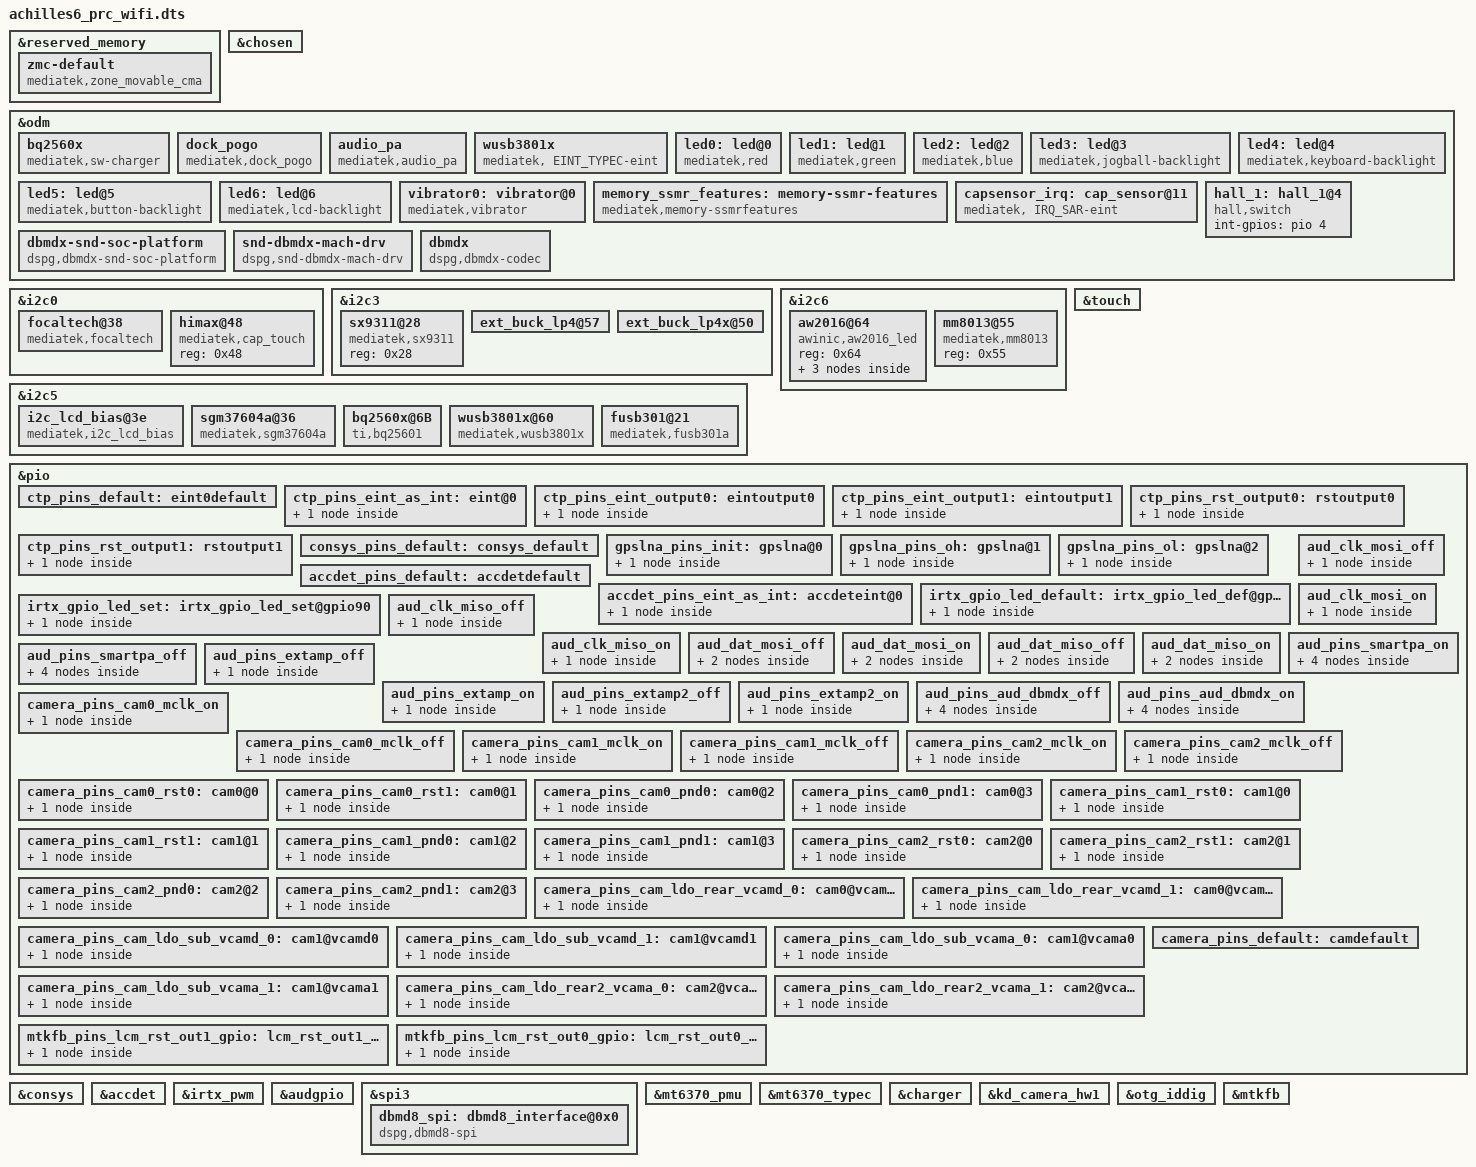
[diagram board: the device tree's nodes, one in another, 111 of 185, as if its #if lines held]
#include <dt-bindings/interrupt-controller/arm-gic.h>
#include <dt-bindings/interrupt-controller/irq.h>
#include <dt-bindings/pinctrl/mt6765-pinfunc.h>
#include <dt-bindings/clock/mt6765-clk.h>
#include <dt-bindings/sound/dspg.h>

/dts-v1/;
/plugin/;
&reserved_memory {
 #address-cells = <2>;
 #size-cells = <2>;
 ranges;
 zmc-default {
 compatible = "mediatek,zone_movable_cma";
 size = <0 0x10000000>;
 alignment = <0 0x10000000>;
 alloc-ranges = <0 0 1 0x00000000>;
 };
};

/* chosen */
&chosen {

	/* fpga may has no lk, we need to specify display info here */
	/* fb buffer is reserved using this dts by memory node above */
	atag,videolfb-fb_base_h = <0x0>;
	atag,videolfb-fb_base_l = <0x5e605000>;
	atag,videolfb-islcmfound = <1>;
	/* because no lk, so lcm is not inited */
	atag,videolfb-islcm_inited = <0>;
	atag,videolfb-fps= <6000>;
	atag,videolfb-vramSize= <0x017bb000>;
	atag,videolfb-lcmname= "nt35695B_fhd_dsi_cmd_auo_rt5081_drv";
};

&odm {
	bq2560x{
		compatible = "mediatek,sw-charger";
		interrupt-parent = <&pio>;
		interrupts = <2 IRQ_TYPE_LEVEL_LOW 2 0>;
		status = "okay";
	};

	dock_pogo{
		compatible = "mediatek,dock_pogo";
		usb_status = <&pio 9 0>;
		dock_status = <&pio 5 0>;
	};

	audio_pa{
		compatible = "mediatek,audio_pa";
		extamp_1 = <&pio 151 0>;
		extamp_2 = <&pio 153 0>;
	};

	wusb3801x {
		compatible = "mediatek, EINT_TYPEC-eint";
		interrupt-parent = <&pio>;
		interrupts = <152 IRQ_TYPE_LEVEL_LOW 152 0>;
		status = "okay";
	};

	led0:led@0 {
		compatible = "mediatek,red";
		led_mode = <0>;
		data = <1>;
		pwm_config = <0 0 0 0 0>;
	};
	led1:led@1 {
		compatible = "mediatek,green";
		led_mode = <0>;
		data = <1>;
		pwm_config = <0 0 0 0 0>;
	};
	led2:led@2 {
		compatible = "mediatek,blue";
		led_mode = <0>;
		data = <1>;
		pwm_config = <0 0 0 0 0>;
	};
	led3:led@3 {
		compatible = "mediatek,jogball-backlight";
		led_mode = <0>;
		data = <1>;
		pwm_config = <0 0 0 0 0>;
	};
	led4:led@4 {
		compatible = "mediatek,keyboard-backlight";
		led_mode = <0>;
		data = <1>;
		pwm_config = <0 0 0 0 0>;
	};
	led5:led@5 {
		compatible = "mediatek,button-backlight";
		led_mode = <0>;
		data = <1>;
		pwm_config = <0 0 0 0 0>;
	};
	led6:led@6 {
		compatible = "mediatek,lcd-backlight";
		led_mode = <4>;
		data = <1>;
		pwm_config = <0 3 0 0 0>;
	};
	vibrator0:vibrator@0 {
		compatible = "mediatek,vibrator";
		vib_timer = <25>;
		vib_limit = <9>;
		vib_vol= <9>;
	};
	memory_ssmr_features: memory-ssmr-features {
		compatible = "mediatek,memory-ssmrfeatures";
		svp-size = <0 0x10000000>;
		iris-recognition-size = <0 0>;
		2d_fr-size = <0 0>;
		tui-size = <0 0>;
		wfd-size = <0 0>;
		prot-sharedmem-size = <0 0>;
	};
	capsensor_irq:cap_sensor@11 {
                compatible = "mediatek, IRQ_SAR-eint";
                interrupt-parent = <&pio>;
		interrupts = <11 IRQ_TYPE_EDGE_FALLING 11 0>;
		status = "okay";
        };
	hall_1:hall_1@4 {
                compatible = "hall,switch";
                int-gpios = <&pio 4 0>;
		status = "okay";
       };

	 dbmdx-snd-soc-platform {
                   compatible = "dspg,dbmdx-snd-soc-platform";
         };

         snd-dbmdx-mach-drv {
                   compatible = "dspg,snd-dbmdx-mach-drv";
         };

	dbmdx {
		status = "okay";
		compatible = "dspg,dbmdx-codec";
		reset_gpio_shared = <0>;
		reset-gpio = <&pio 42 0>;
		sv-gpio = <&pio 7 0>;
		wakeup-gpio = <&pio 6 0>;
		auto_buffering = <1>;
		multi-interface-support = <1>;
		cd-interfaces = < &dbmd8_spi >;
		va-interfaces = <0 0 0 0>;
		feature-va_ve; /* enable VA_VE */
		va-firmware-name = "dbmd8_va_fw.bin";
		va-preboot-firmware-name = "dbmd8_va_preboot_fw.bin";
		va-config =	<DBMDX_VA_EMPTY_CMD
				DBMDX_VA_EMPTY_CMD
				DBMDX_VA_EMPTY_CMD
				(DBMDX_REGN_HOST_INTERFACE_SUPPORT |
					DBMDX_REGV_SPI_D2_TDM1_D4_GPIO_4_5_6_7)
				(DBMDX_REGN_MASTER_CLOCK_FREQUENCY |
#if DBMDX_MCLOCK_VA_24MHZ
					DBMDX_REGV_MCLK_24576000Hz)
#elif DBMDX_MCLOCK_VA_12MHZ
					DBMDX_REGV_MCLK_12288000Hz)
#else /* 32KHZ */
					DBMDX_REGV_MCLK_32768Hz)
#endif
				(DBMDX_REGN_AUDIO_BUFFER_SIZE |
					DBMDX_REGV_AUDIO_BUFFER_3_SEC)
				(DBMDX_REGN_GENERAL_CONFIG_1 |
#ifdef DBMDX_USE_RC_OSC
					DBMDX_REGV_DSP_CLK_GEN_RC_OSC |
#else
					DBMDX_REGV_DSP_CLK_GEN_PLL |
#endif
					DBMDX_REGV_IF_REQUIRED_WAKEUP |
					DBMDX_REGV_SPLIT_MIC_BUFFER |
					DBMDX_REGV_MAX_NUMBER_OF_MIC_IS_2)
																												  
				(DBMDX_REGN_MEMORY_CONFIG |
					DBMDX_REGV_AMODEL_0_LOC_DTCM |
					DBMDX_REGV_AMODEL_1_LOC_DTCM |
					DBMDX_REGV_AMODEL_4_LOC_DTCM |
					DBMDX_REGV_AUDIO_BUF_LOC_DTCM_USING_MEM_ALLOCATION |
#if DBMDX_OKG_WWE_SUPPORT && DBMDX_AMAZON_WWE_SUPPORT
					DBMDX_REGV_AHB_ON_SIZE_192KW_32KW_CACHE_D8 |
#else
					DBMDX_REGV_AHB_ON_SIZE_112KW_32KW_CACHE |
#endif
					DBMDX_REGV_DTCM_SIZE_D4_D6_96_KW_D8_192KW)

				(DBMDX_REGN_GENERAL_CONFIG_2 |
					DBMDX_REGV_MIC_SAMPLE_RATE_16K |
					DBMDX_REGV_DDF_SAMPLE_WIDTH_16_BIT |
					DBMDX_REGV_FW_VAD_TYPE_NO_VAD)
#if DBMDX_USE_ANALOG_MICS
				(DBMDX_REGN_HPF_ENABLE_DISABLE |
					0x0013 )
#else
				(DBMDX_REGN_HPF_ENABLE_DISABLE |
					0x0010 |
					DBMDX_REGV_IIR_HPF_EN |
					DBMDX_REGV_DC_REMOVE_COARSE_EN)
#endif

				(DBMDX_REGN_GPIO_CONFIG |
					DBMDX_REGV_SET_SEC_GPIO |
					DBMDX_REGV_SEC_MODEL_DET_GPIO_NUM_12 |
					DBMDX_REGV_SET_PRI_GPIO |
					DBMDX_REGV_PRI_MODEL_DET_GPIO_NUM_12 )
				(DBMDX_REGN_DSP_CLOCK_CONFIG |
#if DBMDX_MCLOCK_VA_24MHZ
					DBMDX_REGV_PLL_STEP_3 |
#elif DBMDX_MCLOCK_VA_12MHZ
					DBMDX_REGV_PLL_STEP_6 |
#else /* 32Khz */
					DBMDX_REGV_PLL_STEP_4 |
#endif
					DBMDX_REGV_TL3_DIV_1 |
					DBMDX_REGV_APB_DIV_1 |
					DBMDX_REGV_AHB_DIV_3)

				(DBMDX_VA_MSLEEP | 0x0040)
				(DBMDX_REGN_UART_SPEED |
					DBMDX_REGV_UART_BAUD_RATE_3_Mhz)
#ifdef DBMDX_USE_ANALOG_MICS
				(DBMDX_REGN_FIRST_MICROPHONE_CONFIG |
					DBMDX_REGV_DDF_AUDIO_ATTENUATION_0dB |
					DBMDX_REGV_DDF_AND_DM_CONFIG_SAR_DDF_SAR_ADC)
				(DBMDX_REGN_SECOND_MICROPHONE_CONFIG |
					DBMDX_REGV_DDF_AUDIO_ATTENUATION_0dB |
					DBMDX_REGV_DM_CLK_FREQ_1536_1200_SR_8KHz_16KHz_32KHz_48KHz |
					DBMDX_REGV_DDF_AND_DM_CONFIG_SD_DDF_SD_ADC)
#else
				(DBMDX_REGN_FIRST_MICROPHONE_CONFIG |
					DBMDX_REGV_DM_CLOCK_SRC_DM0_GPIO8_DM1_GPIO14 |
		 			DBMDX_REGV_DM_DATA_SRC_DM0_GPIO9_DM1_GPIO13 |
		 			DBMDX_REGV_DDF_AUDIO_ATTENUATION_0dB |
					DBMDX_REGV_DM_CLK_FREQ_1536_1200_SR_8KHz_16KHz_32KHz_48KHz |
					DBMDX_REGV_CLOCK_POLARITY_FALLING_EDGE |
					DBMDX_REGV_DDF_AND_DM_CONFIG_DF0_DM0)
				(DBMDX_REGN_SECOND_MICROPHONE_CONFIG |
					DBMDX_REGV_DM_CLOCK_SRC_DM0_GPIO8_DM1_GPIO14 |
					DBMDX_REGV_DM_DATA_SRC_DM0_GPIO9_DM1_GPIO13 |
					DBMDX_REGV_DDF_AUDIO_ATTENUATION_0dB |
					DBMDX_REGV_DM_CLK_FREQ_1536_1200_SR_8KHz_16KHz_32KHz_48KHz |
					DBMDX_REGV_CLOCK_POLARITY_RISING_EDGE |
					DBMDX_REGV_DDF_AND_DM_CONFIG_DDF1_DM0)
#endif
				(DBMDX_REGN_SECOND_MICROPHONE_CONFIG |
					DBMDX_REGV_CLOSING_MICS_NO_DM_CLOCK)
				(DBMDX_REGN_FIRST_MICROPHONE_CONFIG |
					DBMDX_REGV_CLOSING_MICS_NO_DM_CLOCK)

				DBMDX_VA_EMPTY_CMD
				DBMDX_VA_EMPTY_CMD
				DBMDX_VA_EMPTY_CMD>;

		va-speeds = <0x0000 460800  0 1000000
			     0x0000 2000000 0 3000000
			     0x0000 3000000 0 5000000>;
		va-mic-config = <0x5076 0xa061 0x0A68>;
                va_ve-mic-config = <0x5076 0xa061 0xa093 0x0000>;
                va-mic-mode = <4>;
		master-clk-rate = <32768>;
		default_va_clock = <98304000>;
		/* constant-clk-rate = <32768>; */
		auto_detection = <1>;
		firmware_id = <0xdbd8>;
		wakeup_disabled = <0>;
		use_gpio_for_wakeup = <1>; /* Use wakeup gpio */
		send_wakeup_seq = <0>; /* Send wakup seq */
		wakeup_set_value = <0>;

		uart_low_speed_enabled = <1>;
		detection_buffer_channels = <0>;
		pcm_streaming_mode = <1>;
		boot_options = <0x220>; /* Verify chip id */
		send_uevent_on_detection = <1>;
		send_uevent_after_buffering = <1>;
		detection_after_buffering = <2>;
		change_clock_src_options = <0x4003>;
		va_backlog_length = <502>;
		qed_enabled = <0>;
		low_power_mode_disabled = <0>;
		hw_revision = <0>;
		project_sub_type = <1>;	/* VT ONLY - MELON */
		buffering_timeout = <5>;
		default-streaming-usecase-name = "uc_melon_ga_2mic_aec_48k";
		alsa_streaming_options = <0x8>;
		asrp_tx_out_gain = <0x2cfc>; /* gain=15: (int)((10^(gain/20))*2048) */
		asrp_vcpf_out_gain = <0x2cfc>; /* gain=15: (int)((10^(gain/20))*2048) */
		asrp_rx_out_gain = <0x2cfc>; /* gain=15: (int)((10^(gain/20))*2048) */
		asrp_delay = <1>;
		amodel_options = <1>;
	};

};

&i2c0 {
	focaltech@38 {
		compatible = "mediatek,focaltech";
		reg = <0x38>;
		status = "okay";
		focaltech,usb-charger;
	};

	himax@48 {
		compatible = "mediatek,cap_touch";
		reg = <0x48>;
		status = "okay";
	};
};

&i2c3 {
	sx9311@28 {
                compatible = "mediatek,sx9311";
                reg = <0x28>;
		status = "okay" ;
        };

	ext_buck_lp4@57 {
		regulator-name ="ext_buck_vdd2";
		regulator-min-microvolt = <300000>;
		regulator-max-microvolt = <1300000>;
		vsel_pin = <0>;
	};

	ext_buck_lp4x@50 {
		regulator-name ="ext_buck_vddq";
		regulator-min-microvolt = <300000>;
		regulator-max-microvolt = <1300000>;
		vsel_pin = <1>;
	};
};

&i2c5 {
	i2c_lcd_bias@3e {
		compatible = "mediatek,i2c_lcd_bias";
		reg = <0x3e>;
		bias_gpio_enn = <&pio 168 0>;
		bias_gpio_enp = <&pio 167 0>;
		status = "okay";
	};

	sgm37604a@36 {
		compatible = "mediatek,sgm37604a";
		reg = <0x36>;
		lcm_bl_gpio_enable = <&pio 154 0>;
		status = "okay";
	};
};

&i2c6 {
	aw2016@64 {/* add for breath led. */
		compatible = "awinic,aw2016_led";
		reg = <0x64>;

		aw2016,red {
			aw2016,name = "red";
			aw2016,id = <0>;
			aw2016,imax = <2>;
			aw2016,led-current = <3>;
			aw2016,max-brightness = <255>;
			aw2016,rise-time-ms = <6>;
			aw2016,hold-time-ms = <0>;
			aw2016,fall-time-ms = <6>;
			aw2016,off-time-ms = <4>;
		};

		aw2016,green {
			aw2016,name = "green";
			aw2016,id = <1>;
			aw2016,imax = <3>;
			aw2016,led-current = <3>;
			aw2016,max-brightness = <255>;
			aw2016,rise-time-ms = <6>;
			aw2016,hold-time-ms = <0>;
			aw2016,fall-time-ms = <6>;
			aw2016,off-time-ms = <4>;
		};

		aw2016,blue {
			aw2016,name = "blue";
			aw2016,id = <2>;
			aw2016,imax = <2>;
			aw2016,led-current = <3>;
			aw2016,max-brightness = <255>;
			aw2016,rise-time-ms = <6>;
			aw2016,hold-time-ms = <0>;
			aw2016,fall-time-ms = <6>;
			aw2016,off-time-ms = <4>;
		};
	};
};

/* TOUCH start */
&touch {
	tpd-resolution = <1200 1920>;
	use-tpd-button = <0>;
	tpd-key-num = <3>;
	tpd-key-local= <139 172 158 0>;
	tpd-key-dim-local = <90 883 100 40 230
				 883 100 40 370 883 100 40 0 0 0 0>;
	tpd-max-touch-num = <10>;
	tpd-filter-enable = <0>;
	tpd-filter-pixel-density = <146>;
	tpd-filter-custom-prameters = <0 0 0 0 0 0 0 0 0 0 0 0>;
	tpd-filter-custom-speed = <0 0 0>;
	pinctrl-names = "default", "state_eint_as_int", "state_eint_output0",
		"state_eint_output1", "state_rst_output0", "state_rst_output1";
	pinctrl-0 = <&ctp_pins_default>;
	pinctrl-1 = <&ctp_pins_eint_as_int>;
	pinctrl-2 = <&ctp_pins_eint_output0>;
	pinctrl-3 = <&ctp_pins_eint_output1>;
	pinctrl-4 = <&ctp_pins_rst_output0>;
	pinctrl-5 = <&ctp_pins_rst_output1>;
	status = "okay";
};
&pio {
	ctp_pins_default: eint0default {
	};
	ctp_pins_eint_as_int: eint@0 {
		pins_cmd_dat {
			pinmux = <PINMUX_GPIO10__FUNC_GPIO10>;
			slew-rate = <0>;
			bias-disable;
		};
	};
	ctp_pins_eint_output0: eintoutput0 {
		pins_cmd_dat {
			pinmux = <PINMUX_GPIO10__FUNC_GPIO10>;
			slew-rate = <1>;
			output-low;
		};
	};
	ctp_pins_eint_output1: eintoutput1 {
		pins_cmd_dat {
			pinmux = <PINMUX_GPIO10__FUNC_GPIO10>;
			slew-rate = <1>;
			output-high;
		};
	};
	ctp_pins_rst_output0: rstoutput0 {
		pins_cmd_dat {
			pinmux = <PINMUX_GPIO172__FUNC_GPIO172>;
			slew-rate = <1>;
			output-low;
		};
	};
	ctp_pins_rst_output1: rstoutput1 {
		pins_cmd_dat {
			pinmux = <PINMUX_GPIO172__FUNC_GPIO172>;
			slew-rate = <1>;
			output-high;
		};
	};
};
/* TOUCH end */

/* CONSYS GPIO standardization */
&pio {
	consys_pins_default: consys_default {
	};
	gpslna_pins_init: gpslna@0 {
		pins_cmd_dat {
			pinmux = <PINMUX_GPIO91__FUNC_GPIO91>;
			slew-rate = <0>;
			bias-disable;
			output-low;
		};
	};
	gpslna_pins_oh: gpslna@1 {
		pins_cmd_dat {
			pinmux = <PINMUX_GPIO91__FUNC_GPIO91>;
			slew-rate = <1>;
			output-high;
		};
	};
	gpslna_pins_ol: gpslna@2 {
		pins_cmd_dat {
			pinmux = <PINMUX_GPIO91__FUNC_GPIO91>;
			slew-rate = <1>;
			output-low;
		};
	};
};
&consys {
	pinctrl-names = "default", "gps_lna_state_init",
		"gps_lna_state_oh", "gps_lna_state_ol";
	pinctrl-0 = <&consys_pins_default>;
	pinctrl-1 = <&gpslna_pins_init>;
	pinctrl-2 = <&gpslna_pins_oh>;
	pinctrl-3 = <&gpslna_pins_ol>;
	status = "okay";
};
/* CONSYS end */

/* accdet start */
&accdet {
	accdet-mic-vol = <6>;
	headset-mode-setting = <0x500 0x500 1 0x1f0 0x800 0x800 0x20 0x44>;
	accdet-plugout-debounce = <1>;
	accdet-mic-mode = <1>;
	headset-eint-level-pol = <8>;
	headset-three-key-threshold = <0 80 220 400>;
	headset-three-key-threshold-CDD = <0 121 192 600>;
	headset-four-key-threshold = <0 58 121 192 400>;
	pinctrl-names = "default", "state_eint_as_int";
	pinctrl-0 = <&accdet_pins_default>;
	pinctrl-1 = <&accdet_pins_eint_as_int>;
	status = "okay";
};
&pio {
	accdet_pins_default: accdetdefault {
	};
	accdet_pins_eint_as_int: accdeteint@0 {
		pins_cmd_dat {
			pinmux = <PINMUX_GPIO9__FUNC_GPIO9>;
			slew-rate = <0>;
			bias-disable;
		};
	};
};
/* accdet end */


/* IRTX GPIO end */
&irtx_pwm {
	pinctrl-names = "irtx_gpio_led_default", "irtx_gpio_led_set";
	pinctrl-0 = <&irtx_gpio_led_default>;
	pinctrl-1 = <&irtx_gpio_led_set>;
	status = "okay";
};
&pio {
	irtx_gpio_led_default:irtx_gpio_led_def@gpio90 {
		pins_cmd_dat {
			pinmux = <PINMUX_GPIO90__FUNC_GPIO90>;
			slew-rate = <1>;
			bias-disable;
			output-low;
			input-schmitt-enable = <0>;
		};
	};

	irtx_gpio_led_set:irtx_gpio_led_set@gpio90 {
		pins_cmd_dat {
			pinmux = <PINMUX_GPIO90__FUNC_PWM0>;
			slew-rate = <1>;
			output-high;
		};
	};
};
/* IRTX GPIO Settings -End */

/* AUDIO GPIO standardization */
&audgpio {
	pinctrl-names = "aud_clk_mosi_off",
			"aud_clk_mosi_on",
			"aud_clk_miso_off",
			"aud_clk_miso_on",
			"aud_dat_mosi_off",
			"aud_dat_mosi_on",
			"aud_dat_miso_off",
			"aud_dat_miso_on",
			"aud_smartpa_off",
			"aud_smartpa_on",
			"extamp-pullhigh",
			"extamp-pulllow",
			"extamp2-pullhigh",
			"extamp2-pulllow",
			"aud_dbmdx_off",
			"aud_dbmdx_on";
	pinctrl-0 = <&aud_clk_mosi_off>;
	pinctrl-1 = <&aud_clk_mosi_on>;
	pinctrl-2 = <&aud_clk_miso_off>;
	pinctrl-3 = <&aud_clk_miso_on>;
	pinctrl-4 = <&aud_dat_mosi_off>;
	pinctrl-5 = <&aud_dat_mosi_on>;
	pinctrl-6 = <&aud_dat_miso_off>;
	pinctrl-7 = <&aud_dat_miso_on>;
	pinctrl-8 = <&aud_pins_smartpa_off>;
	pinctrl-9 = <&aud_pins_smartpa_on>;
	pinctrl-10 = <&aud_pins_extamp_on>;
	pinctrl-11 = <&aud_pins_extamp_off>;
	pinctrl-12 = <&aud_pins_extamp2_on>;
	pinctrl-13 = <&aud_pins_extamp2_off>;
	pinctrl-14 = <&aud_pins_aud_dbmdx_off>;
	pinctrl-15 = <&aud_pins_aud_dbmdx_on>;
	status = "okay";
};

&pio {
	aud_clk_mosi_off: aud_clk_mosi_off {
		pins_cmd0_dat {
			pinmux = <PINMUX_GPIO136__FUNC_GPIO136>;
		};
	};

	aud_clk_mosi_on: aud_clk_mosi_on {
		pins_cmd0_dat {
			pinmux = <PINMUX_GPIO136__FUNC_AUD_CLK_MOSI>;
		};
	};

	aud_clk_miso_off: aud_clk_miso_off {
		pins_cmd0_dat {
			pinmux = <PINMUX_GPIO140__FUNC_GPIO140>;
		};
	};

	aud_clk_miso_on: aud_clk_miso_on {
		pins_cmd0_dat {
			pinmux = <PINMUX_GPIO140__FUNC_AUD_CLK_MISO>;
		};
	};

	aud_dat_mosi_off: aud_dat_mosi_off {
		pins_cmd1_dat {
			pinmux = <PINMUX_GPIO138__FUNC_GPIO138>;
			input-enable;
			slew-rate = <0>;
			bias-disable;
		};
		pins_cmd2_dat {
			pinmux = <PINMUX_GPIO139__FUNC_GPIO139>;
			input-enable;
			slew-rate = <0>;
			bias-disable;
		};
	};

	aud_dat_mosi_on: aud_dat_mosi_on {
		pins_cmd1_dat {
			pinmux = <PINMUX_GPIO138__FUNC_AUD_DAT_MOSI0>;
		};
		pins_cmd2_dat {
			pinmux = <PINMUX_GPIO139__FUNC_AUD_DAT_MOSI1>;
		};
	};

	aud_dat_miso_off: aud_dat_miso_off {
		pins_cmd1_dat {
			pinmux = <PINMUX_GPIO142__FUNC_GPIO142>;
			input-enable;
			slew-rate = <0>;
			bias-disable;
		};
		pins_cmd2_dat {
			pinmux = <PINMUX_GPIO143__FUNC_GPIO143>;
			input-enable;
			slew-rate = <0>;
			bias-disable;
		};
	};

	aud_dat_miso_on: aud_dat_miso_on {
		pins_cmd1_dat {
			pinmux = <PINMUX_GPIO142__FUNC_AUD_DAT_MISO0>;
		};
		pins_cmd2_dat {
			pinmux = <PINMUX_GPIO143__FUNC_AUD_DAT_MISO1>;
		};
	};

	aud_pins_smartpa_off: aud_pins_smartpa_off {
		pins_cmd0_dat {
			pinmux = <PINMUX_GPIO17__FUNC_GPIO17>;
		};
		pins_cmd1_dat {
			pinmux = <PINMUX_GPIO18__FUNC_GPIO18>;
		};
		pins_cmd2_dat {
			pinmux = <PINMUX_GPIO19__FUNC_GPIO19>;
		};
		pins_cmd3_dat {
			pinmux = <PINMUX_GPIO20__FUNC_GPIO20>;
		};
	};

	aud_pins_smartpa_on: aud_pins_smartpa_on {
		pins_cmd0_dat {
			pinmux = <PINMUX_GPIO17__FUNC_I2S0_DI>;
		};
		pins_cmd1_dat {
			pinmux = <PINMUX_GPIO18__FUNC_I2S3_BCK>;
		};
		pins_cmd2_dat {
			pinmux = <PINMUX_GPIO19__FUNC_I2S3_LRCK>;
		};
		pins_cmd3_dat {
			pinmux = <PINMUX_GPIO20__FUNC_I2S3_DO>;
		};
	};
	aud_pins_extamp_off: aud_pins_extamp_off {
		pins_cmd_dat {
			pinmux = <PINMUX_GPIO151__FUNC_GPIO151>;
			slew-rate = <1>;
			output-low;
		};
	};
	aud_pins_extamp_on: aud_pins_extamp_on {
		pins_cmd_dat {
			pinmux = <PINMUX_GPIO151__FUNC_GPIO151>;
			slew-rate = <1>;
			output-high;
		};
	};
	aud_pins_extamp2_off: aud_pins_extamp2_off {
		pins_cmd_dat {
			pinmux = <PINMUX_GPIO153__FUNC_GPIO153>;
			slew-rate = <1>;
			output-low;
		};
	};
	aud_pins_extamp2_on: aud_pins_extamp2_on {
		pins_cmd_dat {
			pinmux = <PINMUX_GPIO153__FUNC_GPIO153>;
			slew-rate = <1>;
			output-high;
		};
	};
	aud_pins_aud_dbmdx_off: aud_pins_aud_dbmdx_off {
		pins_cmd0_dat {
			pinmux = <PINMUX_GPIO17__FUNC_GPIO17>;
		};
		pins_cmd1_dat {
			pinmux = <PINMUX_GPIO18__FUNC_GPIO18>;
		};
		pins_cmd2_dat {
			pinmux = <PINMUX_GPIO19__FUNC_GPIO19>;
		};
		pins_cmd3_dat {
			pinmux = <PINMUX_GPIO20__FUNC_GPIO20>;
		};
	};

	aud_pins_aud_dbmdx_on: aud_pins_aud_dbmdx_on {
		pins_cmd0_dat {
			pinmux = <PINMUX_GPIO17__FUNC_I2S0_DI>;
		};
		pins_cmd1_dat {
			pinmux = <PINMUX_GPIO18__FUNC_I2S3_BCK>;
		};
		pins_cmd2_dat {
			pinmux = <PINMUX_GPIO19__FUNC_I2S3_LRCK>;
		};
		pins_cmd3_dat {
			pinmux = <PINMUX_GPIO20__FUNC_I2S3_DO>;
		};
	};
	
};
/* AUDIO end */
/*DSPG start*/
&spi3 {
		status = "okay";
		dbmd8_spi:dbmd8_interface@0x0  {
			compatible = "dspg,dbmd8-spi";
			reg = <0>;
			spi-max-frequency = <125000000>;
			read-chunk-size  = <0x2000> ;
			write-chunk-size = <0x8000> ;
			dma_min_buffer_size = <0>;
		};

};


&mt6370_pmu {
	mt6370,intr_gpio_num = <11>; /* direct defined GPIO num */
	mt6370,intr_gpio = <&pio 11 0x0>;
};

&mt6370_typec {
	mt6370pd,intr_gpio_num = <41>; /* direct defined GPIO num */
	mt6370pd,intr_gpio = <&pio 41 0x0>;
};

&charger {
	algorithm_name = "SwitchCharging";
	chg1_ta_ac_charger_current = <2000000>;
	chg2_ta_ac_charger_current = <2000000>;
};



&pio {
	camera_pins_cam0_mclk_on: camera_pins_cam0_mclk_on {
		pins_cmd_dat {
			pinmux = <PINMUX_GPIO99__FUNC_CMMCLK0>;
		};
	};
	camera_pins_cam0_mclk_off: camera_pins_cam0_mclk_off {
		pins_cmd_dat {
			pinmux = <PINMUX_GPIO99__FUNC_GPIO99>;
		};
	};
	camera_pins_cam1_mclk_on: camera_pins_cam1_mclk_on {
		pins_cmd_dat {
			pinmux = <PINMUX_GPIO100__FUNC_CMMCLK1>;
		};
	};
	camera_pins_cam1_mclk_off: camera_pins_cam1_mclk_off {
		pins_cmd_dat {
			pinmux = <PINMUX_GPIO100__FUNC_GPIO100>;
		};
	};
	camera_pins_cam2_mclk_on: camera_pins_cam2_mclk_on {
		pins_cmd_dat {
			pinmux = <PINMUX_GPIO108__FUNC_CMMCLK2>;
		};
	};
	camera_pins_cam2_mclk_off: camera_pins_cam2_mclk_off {
		pins_cmd_dat {
			pinmux = <PINMUX_GPIO108__FUNC_GPIO108>;
		};
	};
	camera_pins_cam0_rst0: cam0@0 {
		pins_cmd_dat {
			pinmux = <PINMUX_GPIO101__FUNC_GPIO101>;
			slew-rate = <1>;
			output-low;
		};
	};
	camera_pins_cam0_rst1: cam0@1 {
		pins_cmd_dat {
			pinmux = <PINMUX_GPIO101__FUNC_GPIO101>;
			slew-rate = <1>;
			output-high;
		};
	};
	camera_pins_cam0_pnd0: cam0@2 {
		pins_cmd_dat {
			pinmux = <PINMUX_GPIO97__FUNC_GPIO97>;
			slew-rate = <1>;
			output-low;
		};
	};
	camera_pins_cam0_pnd1: cam0@3 {
		pins_cmd_dat {
			pinmux = <PINMUX_GPIO97__FUNC_GPIO97>;
			slew-rate = <1>;
			output-high;
		};
	};
	camera_pins_cam1_rst0: cam1@0 {
		pins_cmd_dat {
			pinmux = <PINMUX_GPIO102__FUNC_GPIO102>;
			slew-rate = <1>;
			output-low;
		};
	};
	camera_pins_cam1_rst1: cam1@1 {
		pins_cmd_dat {
			pinmux = <PINMUX_GPIO102__FUNC_GPIO102>;
			slew-rate = <1>;
			output-high;
		};
	};
	camera_pins_cam1_pnd0: cam1@2 {
		pins_cmd_dat {
			pinmux = <PINMUX_GPIO98__FUNC_GPIO98>;
			slew-rate = <1>;
			output-low;
		};
	};
	camera_pins_cam1_pnd1: cam1@3 {
		pins_cmd_dat {
			pinmux = <PINMUX_GPIO98__FUNC_GPIO98>;
			slew-rate = <1>;
			output-high;
		};
	};
	camera_pins_cam2_rst0: cam2@0 {
		pins_cmd_dat {
			pinmux = <PINMUX_GPIO87__FUNC_GPIO87>;
			slew-rate = <1>;
			output-low;
		};
	};
	camera_pins_cam2_rst1: cam2@1 {
		pins_cmd_dat {
			pinmux = <PINMUX_GPIO87__FUNC_GPIO87>;
			slew-rate = <1>;
			output-high;
		};
	};
	camera_pins_cam2_pnd0: cam2@2 {
		pins_cmd_dat {
			pinmux = <PINMUX_GPIO160__FUNC_GPIO160>;
			slew-rate = <1>;
			output-low;
		};
	};
	camera_pins_cam2_pnd1: cam2@3 {
		pins_cmd_dat {
			pinmux = <PINMUX_GPIO160__FUNC_GPIO160>;
			slew-rate = <1>;
			output-high;
		};
	};
	camera_pins_cam_ldo_rear_vcamd_0: cam0@vcamd0 {
		pins_cmd_dat {
			pinmux = <PINMUX_GPIO88__FUNC_GPIO88>;
			slew-rate = <1>;
			output-low;
		};
	};
	camera_pins_cam_ldo_rear_vcamd_1: cam0@vcamd1 {
		pins_cmd_dat {
			pinmux = <PINMUX_GPIO88__FUNC_GPIO88>;
			slew-rate = <1>;
			output-high;
		};
	};
	camera_pins_cam_ldo_sub_vcamd_0: cam1@vcamd0 {
		pins_cmd_dat {
			pinmux = <PINMUX_GPIO170__FUNC_GPIO170>;
			slew-rate = <1>;
			output-low;
		};
	};
	camera_pins_cam_ldo_sub_vcamd_1: cam1@vcamd1 {
		pins_cmd_dat {
			pinmux = <PINMUX_GPIO170__FUNC_GPIO170>;
			slew-rate = <1>;
			output-high;
		};
	};
	camera_pins_cam_ldo_sub_vcama_0: cam1@vcama0 {
		pins_cmd_dat {
			pinmux = <PINMUX_GPIO169__FUNC_GPIO169>;
			slew-rate = <1>;
			output-low;
		};
	};
	camera_pins_cam_ldo_sub_vcama_1: cam1@vcama1 {
		pins_cmd_dat {
			pinmux = <PINMUX_GPIO169__FUNC_GPIO169>;
			slew-rate = <1>;
			output-high;
		};
	};
	camera_pins_cam_ldo_rear2_vcama_0: cam2@vcama0 {
		pins_cmd_dat {
			pinmux = <PINMUX_GPIO176__FUNC_GPIO176>;
			slew-rate = <1>;
			output-low;
		};
	};
	camera_pins_cam_ldo_rear2_vcama_1: cam2@vcama1 {
		pins_cmd_dat {
			pinmux = <PINMUX_GPIO176__FUNC_GPIO176>;
			slew-rate = <1>;
			output-high;
		};
	};
	camera_pins_default: camdefault {
	};

};

&kd_camera_hw1 {
	pinctrl-names = "default",
			"cam0_rst0",
			"cam0_rst1",
			"cam0_pnd0",
			"cam0_pnd1",
			"cam1_rst0",
			"cam1_rst1",
			"cam1_pnd0",
			"cam1_pnd1",
			"cam2_rst0",
			"cam2_rst1",
			"cam2_pnd0",
			"cam2_pnd1",
			"cam0_vcamd_on",
			"cam0_vcamd_off",
			"cam1_vcamd_on",
			"cam1_vcamd_off",
			"cam1_vcama_on",
			"cam1_vcama_off",
			"cam2_vcama_on",
			"cam2_vcama_off",
			"cam0_mclk_on",
			"cam0_mclk_off",
			"cam1_mclk_on",
			"cam1_mclk_off",
			"cam2_mclk_on",
			"cam2_mclk_off";

	pinctrl-0 = <&camera_pins_default>;
	pinctrl-1 = <&camera_pins_cam0_rst0>;
	pinctrl-2 = <&camera_pins_cam0_rst1>;
	pinctrl-3 = <&camera_pins_cam0_pnd0>;
	pinctrl-4 = <&camera_pins_cam0_pnd1>;
	pinctrl-5 = <&camera_pins_cam1_rst0>;
	pinctrl-6 = <&camera_pins_cam1_rst1>;
	pinctrl-7 = <&camera_pins_cam1_pnd0>;
	pinctrl-8 = <&camera_pins_cam1_pnd1>;
	pinctrl-9 = <&camera_pins_cam2_rst0>;
	pinctrl-10 = <&camera_pins_cam2_rst1>;
	pinctrl-11 = <&camera_pins_cam2_pnd0>;
	pinctrl-12 = <&camera_pins_cam2_pnd1>;
	pinctrl-13 = <&camera_pins_cam_ldo_rear_vcamd_1>;
	pinctrl-14 = <&camera_pins_cam_ldo_rear_vcamd_0>;
	pinctrl-15 = <&camera_pins_cam_ldo_sub_vcamd_1>;
	pinctrl-16 = <&camera_pins_cam_ldo_sub_vcamd_0>;
	pinctrl-17 = <&camera_pins_cam_ldo_sub_vcama_1>;
	pinctrl-18 = <&camera_pins_cam_ldo_sub_vcama_0>;
	pinctrl-19 = <&camera_pins_cam_ldo_rear2_vcama_1>;
	pinctrl-20 = <&camera_pins_cam_ldo_rear2_vcama_0>;
	pinctrl-21 = <&camera_pins_cam0_mclk_on>;
	pinctrl-22 = <&camera_pins_cam0_mclk_off>;
	pinctrl-23 = <&camera_pins_cam1_mclk_on>;
	pinctrl-24 = <&camera_pins_cam1_mclk_off>;
	pinctrl-25 = <&camera_pins_cam2_mclk_on>;
	pinctrl-26 = <&camera_pins_cam2_mclk_off>;
	status = "okay";

};

&otg_iddig{
		status = "okay";
		interrupt-parent = <&pio>;
		interrupts = <41 IRQ_TYPE_LEVEL_LOW 41 0>;
		usb,vbus_gpio = <&pio 169 0>;
		usb,vbus_gpio_num = <169>;
};

&i2c5 {
		bq2560x@6B {
		compatible = "ti,bq25601";
		reg = <0x6B>;
		ti,bq2560x,usb-vlim = <4500>;
		ti,bq2560x,usb-ilim = <500>;
		ti,bq2560x,usb-vreg = <4400>;
		ti,bq2560x,usb-ichg = <500>;

		ti,bq2560x,precharge-current = <256>;
		ti,bq2560x,termination-current = <300>;
		ti,bq2560x,boost-voltage = <4998>;
		ti,bq2560x,boost-current = <500>;
		ti,bq2560x,stat-pin-ctrl = <3>;
		ti,bq2560x,vac-ovp-threshold = <6200>;
		dock,pogo2_en = <&pio 28 0x0>;
		};

		wusb3801x@60{
			compatible = "mediatek,wusb3801x";
			reg = <0x60>;
			wusb3801,irq-gpio = <&pio 152 0x0>;
			wusb3801,init-mode = <0x24>;
			wusb3801,host-current = <0x01>;
			wusb3801,drp-toggle-time = <40>;
		};

		fusb301@21 {
			status = "ok";
			compatible = "mediatek,fusb301a";
			reg = <0x21>;
			fusb301,int-gpio = <&pio 152 0>;
		};

};
&i2c6 {
		mm8013@55 {
		status = "ok";
		compatible = "mediatek,mm8013";
		reg = <0x55>;
		};

};
&charger{
	battery_cv = <4400000>;
	ac_charger_input_current = <2050000>;
	non_std_ac_charger_current = <1550000>;
};

/* DISPSYS GPIO standardization */
&pio {
    mtkfb_pins_lcm_rst_out1_gpio: lcm_rst_out1_gpio {
        pins_cmd_dat {
            pinmux = <PINMUX_GPIO45__FUNC_GPIO45>;
            slew-rate = <1>;
            output-high;
        };
    };

    mtkfb_pins_lcm_rst_out0_gpio: lcm_rst_out0_gpio {
        pins_cmd_dat {
            pinmux = <PINMUX_GPIO45__FUNC_GPIO45>;
            slew-rate = <1>;
            output-low;
        };
    };
};

&mtkfb {
    pinctrl-names =
        "lcm_rst_out1_gpio", "lcm_rst_out0_gpio";
    pinctrl-0 = <&mtkfb_pins_lcm_rst_out1_gpio>;
    pinctrl-1 = <&mtkfb_pins_lcm_rst_out0_gpio>;
    status = "okay";
};

/* DISPSYS GPIO standardization end*/
#include <achilles6_row_wifi/cust.dtsi>
/*End of this file, DO NOT ADD ANYTHING HERE*/
